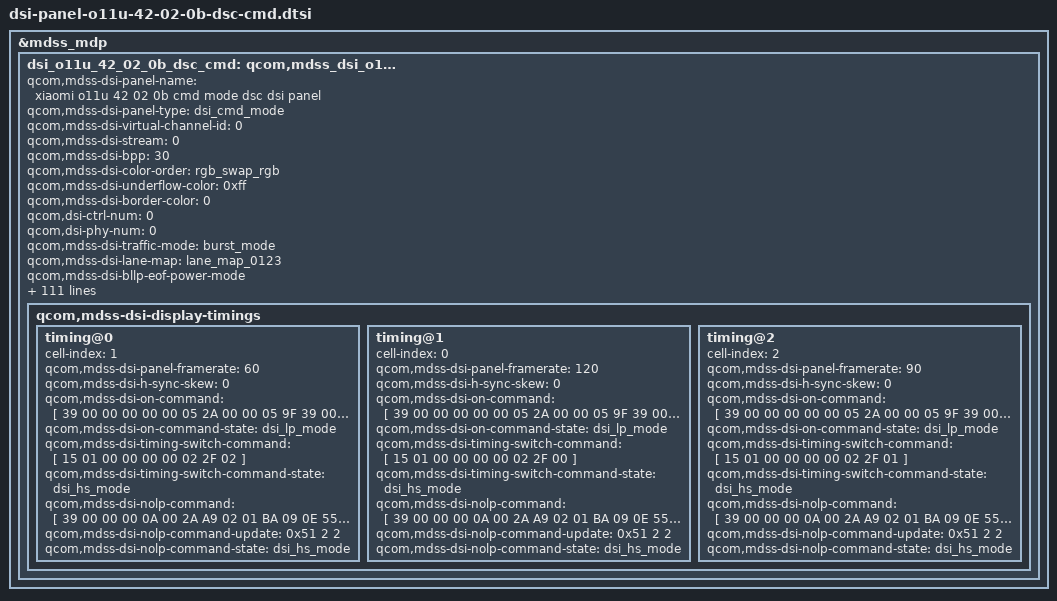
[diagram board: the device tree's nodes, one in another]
/* Panel Attention
 * 1.CCh must be 00 before 51h/26h/38h/39h/gamma change
 */

&mdss_mdp {
	dsi_o11u_42_02_0b_dsc_cmd: qcom,mdss_dsi_o11u_42_02_0b_dsc_cmd {
		qcom,mdss-dsi-panel-name = "xiaomi o11u 42 02 0b cmd mode dsc dsi panel";
		qcom,mdss-dsi-panel-type = "dsi_cmd_mode";
		qcom,mdss-dsi-virtual-channel-id = <0>;
		qcom,mdss-dsi-stream = <0>;
		qcom,mdss-dsi-bpp = <30>;
		qcom,mdss-dsi-color-order = "rgb_swap_rgb";
		qcom,mdss-dsi-underflow-color = <0xff>;
		qcom,mdss-dsi-border-color = <0>;
		qcom,dsi-ctrl-num = <0>;
		qcom,dsi-phy-num = <0>;

		qcom,mdss-dsi-traffic-mode = "burst_mode";
		qcom,mdss-dsi-lane-map = "lane_map_0123";
		qcom,mdss-dsi-bllp-eof-power-mode;
		qcom,mdss-dsi-bllp-power-mode;
		qcom,mdss-dsi-lane-0-state;
		qcom,mdss-dsi-lane-1-state;
		qcom,mdss-dsi-lane-2-state;
		qcom,mdss-dsi-lane-3-state;
		qcom,mdss-dsi-dma-trigger = "trigger_sw";
		qcom,mdss-dsi-mdp-trigger = "none";
		qcom,mdss-dsi-reset-sequence = <1 11>, <0 1>, <1 11>;
		qcom,mdss-pan-physical-width-dimension = <695>;
		qcom,mdss-pan-physical-height-dimension = <1545>;
		qcom,mdss-dsi-te-pin-select = <1>;
		qcom,mdss-dsi-wr-mem-start = <0x2c>;
		qcom,mdss-dsi-wr-mem-continue = <0x3c>;
		qcom,mdss-dsi-te-dcs-command = <1>;
		qcom,mdss-dsi-te-check-enable;
		qcom,mdss-dsi-te-using-te-pin;
		qcom,mdss-dsi-tx-eot-append;
		qcom,mdss-dsi-lp11-init;
		qcom,ulps-enabled;

		qcom,mdss-dsi-bl-inverted-dbv;
		qcom,bl-update-flag = "delay_until_first_frame";

		qcom,mdss-dsi-panel-hdr-enabled;
		qcom,mdss-dsi-panel-hdr-color-primaries = <14500 15500 32000
			17000 15500 30000 8000 3000>;
		qcom,mdss-dsi-panel-peak-brightness = <32000000>;
		qcom,mdss-dsi-panel-blackness-level = <3230>;

		qcom,mdss-dsi-dma-schedule-line = <1>;
		qcom,mdss-dsi-dma-schedule-window = <50>;
		qcom,panel-supply-entries = <&dsi_panel_pwr_supply_o11u>;
		qcom,panel-global-supply-entries = <&dsi_panel_pwr_supply_o11u>;
		qcom,mdss-dsi-bl-pmic-control-type = "bl_ctrl_dcs";
		qcom,mdss-dsi-bl-min-level = <15>;
		qcom,mdss-dsi-bl-max-level = <16383>;
		qcom,bl-dsc-cmd-state = "dsi_hs_mode";
		qcom,mdss-brightness-max-level = <16383>;
		qcom,mdss-brightness-init-level = <614>;
		qcom,platform-reset-gpio = <&tlmm 98 0>;
		qcom,mdss-dsi-panel-vsync-delay;
		qcom,dsi-select-clocks = "pll_byte_clk0", "pll_dsi_clk0";
		qcom,mdss-dsi-clk-strength = <0xFF>;

		qcom,mdss-dsi-display-timings {
			/* 60 Hz */
			timing@0 {
				#include "dsi-panel-o11u-42-02-0a-dsc-cmd-common.dtsi"
				cell-index = <1>;
				qcom,mdss-dsi-panel-framerate = <60>;
				qcom,mdss-dsi-h-sync-skew = <0>;
				qcom,mdss-dsi-on-command = [
					/* 1440 */
					39 00 00 00 00 00 05 2A 00 00 05 9F
					/* 3200 */
					39 00 00 00 00 00 05 2B 00 00 0C 7F
					/* IC SPR */
					39 00 00 40 00 00 03 90 03 43
					39 00 00 40 00 00 13 91 AB A8 00 14 C2 00 02 68 02 2E 00 0A 05 0E 03 D1 10 F0
					39 00 00 40 00 00 06 F0 55 AA 52 08 07
					39 00 00 00 00 00 06 B0 84 40 01 00 00
					/* 60 Hz cmd_1 */
					15 00 00 00 00 00 02 2F 02
					39 00 00 40 00 00 03 51 00 00
					/* idle_dbv */
					15 00 00 40 00 00 02 6F 04
					39 00 00 00 00 00 03 51 0F FF
					/* BCTRL=1 */
					15 00 00 00 00 00 02 53 20
					15 00 00 00 00 00 02 35 00
					15 00 00 40 00 00 02 6F 01
					/* DC_MODE=0 */
					15 00 00 00 00 00 02 8B 00
					/* AOD pulse */
					39 00 00 40 00 00 06 F0 55 AA 52 08 01
					15 00 00 40 00 00 02 6F A2
					39 00 00 40 00 00 06 E7 FF FF FF FF FF
					15 00 00 40 00 00 02 6F 11
					15 00 00 00 00 00 02 E7 08
					/* Show Demura */
					39 00 00 40 00 00 06 F0 55 AA 52 08 00
					15 00 00 40 00 00 02 C7 33
					15 00 00 40 00 00 02 6F 31
					39 00 00 40 00 00 03 C0 00 10
					15 00 00 40 00 00 02 6F 35
					39 00 00 40 00 00 03 C0 22 40
					39 00 00 40 00 00 06 F0 55 AA 52 08 04
					15 00 00 00 00 00 02 C0 20
					/* Demura ON */
					39 00 00 40 00 00 06 F0 55 AA 52 08 04
					15 00 00 00 00 00 02 CA 01
					/* VP_HSSI=1.1 */
					39 00 00 40 00 00 06 F0 55 AA 52 08 01
					15 00 00 40 00 00 02 6F 05
					39 00 00 00 00 00 04 E7 C5 0A 0A
					/* OD ON*/
					39 00 00 40 00 00 06 F0 55 AA 52 08 08
					39 00 00 40 00 00 07 E8 11 90 00 00 00 20
					15 00 00 40 00 00 02 6F 06
					39 00 00 40 00 00 18 E8 00 70 74 74 78 78 7C 7C 7C 7C 7C 7C 7C 7C 78 78 74 74 70 70 64 64 64
					15 00 00 40 00 00 02 6F 1D
					39 00 00 40 00 00 18 E8 00 64 6C 6C 80 80 88 88 88 88 8C 8C 8C 8C 88 88 84 84 84 84 70 70 70
					15 00 00 40 00 00 02 6F 34
					39 00 00 40 00 00 18 E8 00 A4 A8 A8 A8 A8 A8 A8 AC AC AC AC AC AC A8 A8 A4 A4 A4 A4 8C 8C 8C
					39 00 00 40 00 00 06 F0 55 AA 52 08 08
					39 00 00 40 00 00 05 E0 01 01 01 01
					15 00 00 40 00 00 02 6F 06
					39 00 00 40 00 00 0E E0 80 00 21 32 43 54 65 76 87 98 99 99 99
					39 00 00 40 00 00 0F E1 00 00 00 00 00 00 00 00 00 00 01 01 03 03
					15 00 00 40 00 00 02 6F 0E
					39 00 00 40 00 00 0F E1 00 00 00 00 00 00 00 00 00 03 03 03 06 07
					15 00 00 40 00 00 02 6F 1C
					39 00 00 40 00 00 0F E1 00 00 00 00 00 00 00 00 01 02 04 05 0A 0B
					15 00 00 40 00 00 02 6F 2A
					39 00 00 40 00 00 0F E1 00 00 00 00 00 00 00 00 03 04 06 07 0B 0C
					15 00 00 40 00 00 02 6F 38
					39 00 00 40 00 00 0F E1 00 00 00 00 00 00 01 01 04 07 09 0A 0C 0E
					15 00 00 40 00 00 02 6F 46
					39 00 00 40 00 00 0F E1 00 00 00 00 01 01 01 03 04 06 07 09 0A 0B
					15 00 00 40 00 00 02 6F 54
					39 00 00 40 00 00 0F E1 00 00 00 00 01 01 01 03 04 06 07 09 0A 0B
					15 00 00 40 00 00 02 6F 62
					39 00 00 40 00 00 0F E1 00 00 00 00 00 01 01 01 03 05 08 0C 0D 0E
					15 00 00 40 00 00 02 6F 70
					39 00 00 40 00 00 0F E1 00 00 00 00 01 02 02 03 05 06 09 0B 0E 10
					39 00 00 40 00 00 0F E2 01 01 01 02 19 1A 10 0F 0F 17 08 12 15 1E
					15 00 00 40 00 00 02 6F 0E
					39 00 00 40 00 00 0F E2 04 08 0B 0F 11 11 13 13 0C 0C 0A 0B 12 13
					15 00 00 40 00 00 02 6F 1C
					39 00 00 40 00 00 0F E2 02 04 05 07 0A 0D 0F 0D 06 09 0A 0E 0F 10
					15 00 00 40 00 00 02 6F 2A
					39 00 00 40 00 00 0F E2 02 04 0A 0B 02 03 06 07 07 09 0B 0C 0F 12
					15 00 00 40 00 00 02 6F 38
					39 00 00 40 00 00 0F E2 03 05 05 08 02 02 04 05 05 08 0B 0D 10 11
					15 00 00 40 00 00 02 6F 46
					39 00 00 40 00 00 0F E2 02 02 03 05 02 01 04 05 07 09 0A 0C 0F 11
					15 00 00 40 00 00 02 6F 54
					39 00 00 40 00 00 0F E2 02 02 03 05 02 01 04 05 07 09 0A 0C 0F 11
					15 00 00 40 00 00 02 6F 62
					39 00 00 40 00 00 0F E2 01 01 02 02 01 01 03 03 07 08 09 0D 0D 11
					15 00 00 40 00 00 02 6F 70
					39 00 00 40 00 00 0F E2 00 00 01 01 01 01 03 04 06 08 09 0B 0F 11
					39 00 00 40 00 00 0F E3 00 00 00 00 00 00 00 00 00 00 02 02 07 07
					15 00 00 40 00 00 02 6F 0E
					39 00 00 40 00 00 0F E3 00 00 00 00 00 00 01 01 01 02 04 04 0E 0E
					15 00 00 40 00 00 02 6F 1C
					39 00 00 40 00 00 0F E3 00 00 00 00 00 01 01 01 01 04 03 05 08 0E
					15 00 00 40 00 00 02 6F 2A
					39 00 00 40 00 00 0F E3 00 00 00 00 00 01 02 02 02 06 08 0C 0D 0F
					15 00 00 40 00 00 02 6F 38
					39 00 00 40 00 00 0F E3 00 00 00 00 00 01 02 02 05 06 0A 0A 0C 0F
					15 00 00 40 00 00 02 6F 46
					39 00 00 40 00 00 0F E3 00 00 00 00 00 01 02 02 04 07 06 0A 0B 0D
					15 00 00 40 00 00 02 6F 54
					39 00 00 40 00 00 0F E3 00 00 00 00 00 01 02 02 04 07 06 0A 0B 0D
					15 00 00 40 00 00 02 6F 62
					39 00 00 40 00 00 0F E3 00 00 01 01 01 02 03 04 05 07 0A 0C 0F 11
					15 00 00 40 00 00 02 6F 70
					39 00 00 40 00 00 0F E3 00 01 01 01 01 01 02 03 06 07 0A 0D 0F 12
					39 00 00 40 00 00 1C EA 00 00 00 00 00 00 00 00 00 00 00 00 00 00 00 00 00 00 00 00 00 00 00 00 00 00 00
					39 00 00 40 00 00 0A E4 00 00 00 00 00 00 00 00 00
					39 00 00 40 00 00 0A E5 00 00 00 00 00 00 00 00 00
					39 00 00 40 00 00 0A E6 00 00 00 00 00 00 00 00 00
					39 00 00 40 00 00 06 F0 55 AA 52 08 08
					15 00 00 40 00 00 02 E8 11
					15 00 00 00 00 00 02 E0 01
					/* ESD ERR Flag */
					39 00 00 40 00 00 06 F0 55 AA 52 08 00
					39 00 00 40 00 00 03 BE 47 45
					15 00 00 40 00 00 02 6F 05
					15 00 00 00 00 00 02 BE 08
					/*  ESD MIPI error */
					39 00 00 40 00 00 06 F0 55 AA 52 08 03
					39 00 00 00 00 00 04 C8 01 02 03
					/* MIPI error */
					39 00 00 40 00 00 05 FF AA 55 A5 80
					15 00 00 40 00 00 02 6F 22
					15 00 00 00 00 00 02 FE 06
					/*MIPI optimize code1 */
					39 00 00 40 00 00 05 FF AA 55 A5 82
					15 00 00 40 00 00 02 6F 05
					15 00 00 00 00 00 02 F3 11
					/*MIPI optimize code2 */
					39 00 00 40 00 00 06 F0 55 AA 52 08 01
					15 00 00 40 00 00 02 6F 05
					39 00 00 00 00 00 03 C5 0A 0A
					/* APL Data scaling */
					39 00 00 40 00 00 06 F0 55 AA 52 08 00
					15 00 00 40 00 00 02 6F 78
					39 00 00 40 00 00 18 B0 11 00 2A 00 C2 01 DA 03 7C 05 B1 08 80 0B EE 0F FF 05 55 05 56 05 55
					15 00 00 40 00 00 02 6F 6F
					39 00 00 40 00 00 07 B0 02 D0 05 A0 02 D0
					39 00 00 40 00 00 06 F0 55 AA 52 08 08
					39 00 00 40 00 00 17 C1 8C FF CC FF FF CC FF FF CC FF FF EC FF 7F EE 7F 7F FF 7F FF 0E 7F
					15 00 00 40 00 00 02 6F 20
					39 00 00 40 00 00 04 C1 4F 00 FF
					15 00 00 40 00 00 02 6F 23
					39 00 00 00 00 00 15 C1 0C FF CC FF FF CC FF FF CC FF FF EC FF 7F EE 7F 7F CF 7F 0A
					/* Round ON */
					39 00 00 40 00 00 06 F0 55 AA 52 08 07
					15 00 00 00 00 00 02 C0 87
					/* OSC=125.2MHz, 1200Mbps */
					39 00 00 00 00 00 EE A9 02 01 C3 00 00 99 02 01 C3 30 30 00 02 01 C3 0B 0D 3F 20 2F 02 01 C3 11 13 3F 70 2F 02 01 C3 17 17 3F 02 01 C3 18 19 26 2F 02 01 C3 1D 1F 3F 20 2F 02 01 C3 23 25 3F 3A 2F 02 01 C3 0E 0F 3F 62 02 01 C3 10 10 DE 02 01 C3 14 16 3F 62 DE 02 01 C3 1A 1C 3F 62 DE 02 01 C3 20 22 3F 62 DE 02 01 C3 26 27 3F 62 02 01 C3 28 28 DE 02 01 C3 29 2B 11 11 01 02 01 C3 2C 2E 00 00 00 02 01 C3 31 32 AA 02 02 01 C3 33 34 AA 02 02 01 C3 04 04 E3 02 01 C3 09 09 E4 02 01 C3 01 01 29 02 01 C3 06 06 29 02 01 C3 02 03 02 70 02 01 C3 08 08 70 02 01 EA 00 00 11 02 01 EA 07 07 01 02 01 EA 08 08 39 02 01 EA 0B 0B 11 02 01 EA 12 13 01 AC 02 01 EA 1A 1B 01 39 02 01 EA 1C 1D 01 AC 02 01 C3 04 04 EA 02 01 C3 09 09 EA 02 01 C3 2F 2F 77
					/*DDIC Fast Discharge On*/
					39 00 00 40 00 00 06 F0 55 AA 52 08 01
					15 00 00 40 00 00 02 E4 90
					15 00 00 40 00 00 02 6F 0A
					15 00 00 00 00 00 02 E4 90
					/* Fix TE Width */
					39 00 00 00 00 00 03 35 20 2E
					/* Abnormal power failure */
					39 00 00 00 00 00 06 F0 55 AA 52 08 05
					39 00 00 00 00 00 08 CB 13 13 13 13 13 13 13
					/* Sleep Out */
					05 00 00 00 78 00 02 11 00
					/* Demura offset remapping open */
					39 00 00 40 00 00 06 F0 55 AA 52 08 04
					15 00 00 00 00 00 02 EB 00
					/* Display On */
					05 00 00 00 00 00 02 29 00
				];
				qcom,mdss-dsi-on-command-state = "dsi_lp_mode";
				qcom,mdss-dsi-timing-switch-command = [
					/* 60 Hz cmd_1 */
					15 01 00 00 00 00 02 2F 02
				];
				qcom,mdss-dsi-timing-switch-command-state = "dsi_hs_mode";

				qcom,mdss-dsi-nolp-command = [
					39 00 00 00 0A 00 2A A9 02 01 BA 09 0E 55 55 55 55 AA 3F 02 01 BA 1B 1C 92 92 02 01 BA 27 27 55 02 01 BA 28 2C 55 55 55 AA 3F 02 01 BA 39 3A 92 92
					05 00 00 40 00 00 01 38
					39 00 00 40 00 00 03 51 00 23
					15 00 00 00 00 00 02 2F 02
				];
				qcom,mdss-dsi-nolp-command-update = <0x51 2 2>;
				qcom,mdss-dsi-nolp-command-state = "dsi_hs_mode";

			};

			/* 120 Hz */
			timing@1 {
				#include "dsi-panel-o11u-42-02-0a-dsc-cmd-common.dtsi"
				cell-index = <0>;
				qcom,mdss-dsi-panel-framerate = <120>;
				qcom,mdss-dsi-h-sync-skew = <0>;
				qcom,mdss-dsi-on-command = [
					/* 1440 */
					39 00 00 00 00 00 05 2A 00 00 05 9F
					/* 3200 */
					39 00 00 00 00 00 05 2B 00 00 0C 7F
					/* IC SPR */
					39 00 00 40 00 00 03 90 03 43
					39 00 00 40 00 00 13 91 AB A8 00 14 C2 00 02 68 02 2E 00 0A 05 0E 03 D1 10 F0
					39 00 00 40 00 00 06 F0 55 AA 52 08 07
					39 00 00 00 00 00 06 B0 84 40 01 00 00
					/* 120 Hz cmd_1 */
					15 00 00 00 00 00 02 2F 00
					39 00 00 40 00 00 03 51 00 00
					/* idle_dbv */
					15 00 00 40 00 00 02 6F 04
					39 00 00 00 00 00 03 51 0F FF
					/* BCTRL=1 */
					15 00 00 00 00 00 02 53 20
					15 00 00 00 00 00 02 35 00
					15 00 00 40 00 00 02 6F 01
					/* DC_MODE=0 */
					15 00 00 00 00 00 02 8B 00
					/* AOD pulse */
					39 00 00 40 00 00 06 F0 55 AA 52 08 01
					15 00 00 40 00 00 02 6F A2
					39 00 00 40 00 00 06 E7 FF FF FF FF FF
					15 00 00 40 00 00 02 6F 11
					15 00 00 00 00 00 02 E7 08
					/* Show Demura */
					39 00 00 40 00 00 06 F0 55 AA 52 08 00
					15 00 00 40 00 00 02 C7 33
					15 00 00 40 00 00 02 6F 31
					39 00 00 40 00 00 03 C0 00 10
					15 00 00 40 00 00 02 6F 35
					39 00 00 40 00 00 03 C0 22 40
					39 00 00 40 00 00 06 F0 55 AA 52 08 04
					15 00 00 00 00 00 02 C0 20
					/* Demura ON */
					39 00 00 40 00 00 06 F0 55 AA 52 08 04
					15 00 00 00 00 00 02 CA 01
					/* VP_HSSI=1.1 */
					39 00 00 40 00 00 06 F0 55 AA 52 08 01
					15 00 00 40 00 00 02 6F 05
					39 00 00 00 00 00 04 E7 C5 0A 0A
					/* OD ON*/
					39 00 00 40 00 00 06 F0 55 AA 52 08 08
					39 00 00 40 00 00 07 E8 11 90 00 00 00 20
					15 00 00 40 00 00 02 6F 06
					39 00 00 40 00 00 18 E8 00 70 74 74 78 78 7C 7C 7C 7C 7C 7C 7C 7C 78 78 74 74 70 70 64 64 64
					15 00 00 40 00 00 02 6F 1D
					39 00 00 40 00 00 18 E8 00 64 6C 6C 80 80 88 88 88 88 8C 8C 8C 8C 88 88 84 84 84 84 70 70 70
					15 00 00 40 00 00 02 6F 34
					39 00 00 40 00 00 18 E8 00 A4 A8 A8 A8 A8 A8 A8 AC AC AC AC AC AC A8 A8 A4 A4 A4 A4 8C 8C 8C
					39 00 00 40 00 00 06 F0 55 AA 52 08 08
					39 00 00 40 00 00 05 E0 01 01 01 01
					15 00 00 40 00 00 02 6F 06
					39 00 00 40 00 00 0E E0 80 00 21 32 43 54 65 76 87 98 99 99 99
					39 00 00 40 00 00 0F E1 00 00 00 00 00 00 00 00 00 00 01 01 03 03
					15 00 00 40 00 00 02 6F 0E
					39 00 00 40 00 00 0F E1 00 00 00 00 00 00 00 00 00 03 03 03 06 07
					15 00 00 40 00 00 02 6F 1C
					39 00 00 40 00 00 0F E1 00 00 00 00 00 00 00 00 01 02 04 05 0A 0B
					15 00 00 40 00 00 02 6F 2A
					39 00 00 40 00 00 0F E1 00 00 00 00 00 00 00 00 03 04 06 07 0B 0C
					15 00 00 40 00 00 02 6F 38
					39 00 00 40 00 00 0F E1 00 00 00 00 00 00 01 01 04 07 09 0A 0C 0E
					15 00 00 40 00 00 02 6F 46
					39 00 00 40 00 00 0F E1 00 00 00 00 01 01 01 03 04 06 07 09 0A 0B
					15 00 00 40 00 00 02 6F 54
					39 00 00 40 00 00 0F E1 00 00 00 00 01 01 01 03 04 06 07 09 0A 0B
					15 00 00 40 00 00 02 6F 62
					39 00 00 40 00 00 0F E1 00 00 00 00 00 01 01 01 03 05 08 0C 0D 0E
					15 00 00 40 00 00 02 6F 70
					39 00 00 40 00 00 0F E1 00 00 00 00 01 02 02 03 05 06 09 0B 0E 10
					39 00 00 40 00 00 0F E2 01 01 01 02 19 1A 10 0F 0F 17 08 12 15 1E
					15 00 00 40 00 00 02 6F 0E
					39 00 00 40 00 00 0F E2 04 08 0B 0F 11 11 13 13 0C 0C 0A 0B 12 13
					15 00 00 40 00 00 02 6F 1C
					39 00 00 40 00 00 0F E2 02 04 05 07 0A 0D 0F 0D 06 09 0A 0E 0F 10
					15 00 00 40 00 00 02 6F 2A
					39 00 00 40 00 00 0F E2 02 04 0A 0B 02 03 06 07 07 09 0B 0C 0F 12
					15 00 00 40 00 00 02 6F 38
					39 00 00 40 00 00 0F E2 03 05 05 08 02 02 04 05 05 08 0B 0D 10 11
					15 00 00 40 00 00 02 6F 46
					39 00 00 40 00 00 0F E2 02 02 03 05 02 01 04 05 07 09 0A 0C 0F 11
					15 00 00 40 00 00 02 6F 54
					39 00 00 40 00 00 0F E2 02 02 03 05 02 01 04 05 07 09 0A 0C 0F 11
					15 00 00 40 00 00 02 6F 62
					39 00 00 40 00 00 0F E2 01 01 02 02 01 01 03 03 07 08 09 0D 0D 11
					15 00 00 40 00 00 02 6F 70
					39 00 00 40 00 00 0F E2 00 00 01 01 01 01 03 04 06 08 09 0B 0F 11
					39 00 00 40 00 00 0F E3 00 00 00 00 00 00 00 00 00 00 02 02 07 07
					15 00 00 40 00 00 02 6F 0E
					39 00 00 40 00 00 0F E3 00 00 00 00 00 00 01 01 01 02 04 04 0E 0E
					15 00 00 40 00 00 02 6F 1C
					39 00 00 40 00 00 0F E3 00 00 00 00 00 01 01 01 01 04 03 05 08 0E
					15 00 00 40 00 00 02 6F 2A
					39 00 00 40 00 00 0F E3 00 00 00 00 00 01 02 02 02 06 08 0C 0D 0F
					15 00 00 40 00 00 02 6F 38
					39 00 00 40 00 00 0F E3 00 00 00 00 00 01 02 02 05 06 0A 0A 0C 0F
					15 00 00 40 00 00 02 6F 46
					39 00 00 40 00 00 0F E3 00 00 00 00 00 01 02 02 04 07 06 0A 0B 0D
					15 00 00 40 00 00 02 6F 54
					39 00 00 40 00 00 0F E3 00 00 00 00 00 01 02 02 04 07 06 0A 0B 0D
					15 00 00 40 00 00 02 6F 62
					39 00 00 40 00 00 0F E3 00 00 01 01 01 02 03 04 05 07 0A 0C 0F 11
					15 00 00 40 00 00 02 6F 70
					39 00 00 40 00 00 0F E3 00 01 01 01 01 01 02 03 06 07 0A 0D 0F 12
					39 00 00 40 00 00 1C EA 00 00 00 00 00 00 00 00 00 00 00 00 00 00 00 00 00 00 00 00 00 00 00 00 00 00 00
					39 00 00 40 00 00 0A E4 00 00 00 00 00 00 00 00 00
					39 00 00 40 00 00 0A E5 00 00 00 00 00 00 00 00 00
					39 00 00 40 00 00 0A E6 00 00 00 00 00 00 00 00 00
					39 00 00 40 00 00 06 F0 55 AA 52 08 08
					15 00 00 40 00 00 02 E8 11
					15 00 00 00 00 00 02 E0 01
					/* ESD ERR Flag */
					39 00 00 40 00 00 06 F0 55 AA 52 08 00
					39 00 00 40 00 00 03 BE 47 45
					15 00 00 40 00 00 02 6F 05
					15 00 00 00 00 00 02 BE 08
					/*  ESD MIPI error */
					39 00 00 40 00 00 06 F0 55 AA 52 08 03
					39 00 00 00 00 00 04 C8 01 02 03
					/* MIPI error */
					39 00 00 40 00 00 05 FF AA 55 A5 80
					15 00 00 40 00 00 02 6F 22
					15 00 00 00 00 00 02 FE 06
					/*MIPI optimize code1 */
					39 00 00 40 00 00 05 FF AA 55 A5 82
					15 00 00 40 00 00 02 6F 05
					15 00 00 00 00 00 02 F3 11
					/*MIPI optimize code2 */
					39 00 00 40 00 00 06 F0 55 AA 52 08 01
					15 00 00 40 00 00 02 6F 05
					39 00 00 00 00 00 03 C5 0A 0A
					/* APL Data scaling */
					39 00 00 40 00 00 06 F0 55 AA 52 08 00
					15 00 00 40 00 00 02 6F 78
					39 00 00 40 00 00 18 B0 11 00 2A 00 C2 01 DA 03 7C 05 B1 08 80 0B EE 0F FF 05 55 05 56 05 55
					15 00 00 40 00 00 02 6F 6F
					39 00 00 40 00 00 07 B0 02 D0 05 A0 02 D0
					39 00 00 40 00 00 06 F0 55 AA 52 08 08
					39 00 00 40 00 00 17 C1 8C FF CC FF FF CC FF FF CC FF FF EC FF 7F EE 7F 7F FF 7F FF 0E 7F
					15 00 00 40 00 00 02 6F 20
					39 00 00 40 00 00 04 C1 4F 00 FF
					15 00 00 40 00 00 02 6F 23
					39 00 00 00 00 00 15 C1 0C FF CC FF FF CC FF FF CC FF FF EC FF 7F EE 7F 7F CF 7F 0A
					/* Round ON */
					39 00 00 40 00 00 06 F0 55 AA 52 08 07
					15 00 00 00 00 00 02 C0 87
					/* OSC=125.2MHz, 1200Mbps */
					39 00 00 00 00 00 EE A9 02 01 C3 00 00 99 02 01 C3 30 30 00 02 01 C3 0B 0D 3F 20 2F 02 01 C3 11 13 3F 70 2F 02 01 C3 17 17 3F 02 01 C3 18 19 26 2F 02 01 C3 1D 1F 3F 20 2F 02 01 C3 23 25 3F 3A 2F 02 01 C3 0E 0F 3F 62 02 01 C3 10 10 DE 02 01 C3 14 16 3F 62 DE 02 01 C3 1A 1C 3F 62 DE 02 01 C3 20 22 3F 62 DE 02 01 C3 26 27 3F 62 02 01 C3 28 28 DE 02 01 C3 29 2B 11 11 01 02 01 C3 2C 2E 00 00 00 02 01 C3 31 32 AA 02 02 01 C3 33 34 AA 02 02 01 C3 04 04 E3 02 01 C3 09 09 E4 02 01 C3 01 01 29 02 01 C3 06 06 29 02 01 C3 02 03 02 70 02 01 C3 08 08 70 02 01 EA 00 00 11 02 01 EA 07 07 01 02 01 EA 08 08 39 02 01 EA 0B 0B 11 02 01 EA 12 13 01 AC 02 01 EA 1A 1B 01 39 02 01 EA 1C 1D 01 AC 02 01 C3 04 04 EA 02 01 C3 09 09 EA 02 01 C3 2F 2F 77
					/*DDIC Fast Discharge On*/
					39 00 00 40 00 00 06 F0 55 AA 52 08 01
					15 00 00 40 00 00 02 E4 90
					15 00 00 40 00 00 02 6F 0A
					15 00 00 00 00 00 02 E4 90
					/* Fix TE Width */
					39 00 00 00 00 00 03 35 20 2E
					/* Abnormal power failure */
					39 00 00 00 00 00 06 F0 55 AA 52 08 05
					39 00 00 00 00 00 08 CB 13 13 13 13 13 13 13
					/* Sleep Out */
					05 00 00 00 78 00 02 11 00
					/* Demura offset remapping open */
					39 00 00 40 00 00 06 F0 55 AA 52 08 04
					15 00 00 00 00 00 02 EB 00
					/* Display On */
					05 00 00 00 00 00 02 29 00
				];
				qcom,mdss-dsi-on-command-state = "dsi_lp_mode";

				qcom,mdss-dsi-timing-switch-command = [
					/* 120 Hz cmd_1 */
					15 01 00 00 00 00 02 2F 00
				];
				qcom,mdss-dsi-timing-switch-command-state = "dsi_hs_mode";

				qcom,mdss-dsi-nolp-command = [
					39 00 00 00 0A 00 2A A9 02 01 BA 09 0E 55 55 55 55 AA 3F 02 01 BA 1B 1C 92 92 02 01 BA 27 27 55 02 01 BA 28 2C 55 55 55 AA 3F 02 01 BA 39 3A 92 92
					05 00 00 40 00 00 01 38
					39 00 00 40 00 00 03 51 00 23
					15 00 00 00 00 00 02 2F 00
				];
				qcom,mdss-dsi-nolp-command-update = <0x51 2 2>;
				qcom,mdss-dsi-nolp-command-state = "dsi_hs_mode";
			};

			/* 90 Hz */
			timing@2 {
				#include "dsi-panel-o11u-42-02-0a-dsc-cmd-common.dtsi"
				cell-index = <2>;
				qcom,mdss-dsi-panel-framerate = <90>;
				qcom,mdss-dsi-h-sync-skew = <0>;
				qcom,mdss-dsi-on-command = [
					/* 1440 */
					39 00 00 00 00 00 05 2A 00 00 05 9F
					/* 3200 */
					39 00 00 00 00 00 05 2B 00 00 0C 7F
					/* IC SPR */
					39 00 00 40 00 00 03 90 03 43
					39 00 00 40 00 00 13 91 AB A8 00 14 C2 00 02 68 02 2E 00 0A 05 0E 03 D1 10 F0
					39 00 00 40 00 00 06 F0 55 AA 52 08 07
					39 00 00 00 00 00 06 B0 84 40 01 00 00
					/* 90 Hz cmd_1 */
					15 00 00 00 00 00 02 2F 01
					39 00 00 40 00 00 03 51 00 00
					/* idle_dbv */
					15 00 00 40 00 00 02 6F 04
					39 00 00 00 00 00 03 51 0F FF
					/* BCTRL=1 */
					15 00 00 00 00 00 02 53 20
					15 00 00 00 00 00 02 35 00
					15 00 00 40 00 00 02 6F 01
					/* DC_MODE=0 */
					15 00 00 00 00 00 02 8B 00
					/* AOD pulse */
					39 00 00 40 00 00 06 F0 55 AA 52 08 01
					15 00 00 40 00 00 02 6F A2
					39 00 00 40 00 00 06 E7 FF FF FF FF FF
					15 00 00 40 00 00 02 6F 11
					15 00 00 00 00 00 02 E7 08
					/* Show Demura */
					39 00 00 40 00 00 06 F0 55 AA 52 08 00
					15 00 00 40 00 00 02 C7 33
					15 00 00 40 00 00 02 6F 31
					39 00 00 40 00 00 03 C0 00 10
					15 00 00 40 00 00 02 6F 35
					39 00 00 40 00 00 03 C0 22 40
					39 00 00 40 00 00 06 F0 55 AA 52 08 04
					15 00 00 00 00 00 02 C0 20
					/* Demura ON */
					39 00 00 40 00 00 06 F0 55 AA 52 08 04
					15 00 00 00 00 00 02 CA 01
					/* VP_HSSI=1.1 */
					39 00 00 40 00 00 06 F0 55 AA 52 08 01
					15 00 00 40 00 00 02 6F 05
					39 00 00 00 00 00 04 E7 C5 0A 0A
					/* OD ON*/
					39 00 00 40 00 00 06 F0 55 AA 52 08 08
					39 00 00 40 00 00 07 E8 11 90 00 00 00 20
					15 00 00 40 00 00 02 6F 06
					39 00 00 40 00 00 18 E8 00 70 74 74 78 78 7C 7C 7C 7C 7C 7C 7C 7C 78 78 74 74 70 70 64 64 64
					15 00 00 40 00 00 02 6F 1D
					39 00 00 40 00 00 18 E8 00 64 6C 6C 80 80 88 88 88 88 8C 8C 8C 8C 88 88 84 84 84 84 70 70 70
					15 00 00 40 00 00 02 6F 34
					39 00 00 40 00 00 18 E8 00 A4 A8 A8 A8 A8 A8 A8 AC AC AC AC AC AC A8 A8 A4 A4 A4 A4 8C 8C 8C
					39 00 00 40 00 00 06 F0 55 AA 52 08 08
					39 00 00 40 00 00 05 E0 01 01 01 01
					15 00 00 40 00 00 02 6F 06
					39 00 00 40 00 00 0E E0 80 00 21 32 43 54 65 76 87 98 99 99 99
					39 00 00 40 00 00 0F E1 00 00 00 00 00 00 00 00 00 00 01 01 03 03
					15 00 00 40 00 00 02 6F 0E
					39 00 00 40 00 00 0F E1 00 00 00 00 00 00 00 00 00 03 03 03 06 07
					15 00 00 40 00 00 02 6F 1C
					39 00 00 40 00 00 0F E1 00 00 00 00 00 00 00 00 01 02 04 05 0A 0B
					15 00 00 40 00 00 02 6F 2A
					39 00 00 40 00 00 0F E1 00 00 00 00 00 00 00 00 03 04 06 07 0B 0C
					15 00 00 40 00 00 02 6F 38
					39 00 00 40 00 00 0F E1 00 00 00 00 00 00 01 01 04 07 09 0A 0C 0E
					15 00 00 40 00 00 02 6F 46
					39 00 00 40 00 00 0F E1 00 00 00 00 01 01 01 03 04 06 07 09 0A 0B
					15 00 00 40 00 00 02 6F 54
					39 00 00 40 00 00 0F E1 00 00 00 00 01 01 01 03 04 06 07 09 0A 0B
					15 00 00 40 00 00 02 6F 62
					39 00 00 40 00 00 0F E1 00 00 00 00 00 01 01 01 03 05 08 0C 0D 0E
					15 00 00 40 00 00 02 6F 70
					39 00 00 40 00 00 0F E1 00 00 00 00 01 02 02 03 05 06 09 0B 0E 10
					39 00 00 40 00 00 0F E2 01 01 01 02 19 1A 10 0F 0F 17 08 12 15 1E
					15 00 00 40 00 00 02 6F 0E
					39 00 00 40 00 00 0F E2 04 08 0B 0F 11 11 13 13 0C 0C 0A 0B 12 13
					15 00 00 40 00 00 02 6F 1C
					39 00 00 40 00 00 0F E2 02 04 05 07 0A 0D 0F 0D 06 09 0A 0E 0F 10
					15 00 00 40 00 00 02 6F 2A
					39 00 00 40 00 00 0F E2 02 04 0A 0B 02 03 06 07 07 09 0B 0C 0F 12
					15 00 00 40 00 00 02 6F 38
					39 00 00 40 00 00 0F E2 03 05 05 08 02 02 04 05 05 08 0B 0D 10 11
					15 00 00 40 00 00 02 6F 46
					39 00 00 40 00 00 0F E2 02 02 03 05 02 01 04 05 07 09 0A 0C 0F 11
					15 00 00 40 00 00 02 6F 54
					39 00 00 40 00 00 0F E2 02 02 03 05 02 01 04 05 07 09 0A 0C 0F 11
					15 00 00 40 00 00 02 6F 62
					39 00 00 40 00 00 0F E2 01 01 02 02 01 01 03 03 07 08 09 0D 0D 11
					15 00 00 40 00 00 02 6F 70
					39 00 00 40 00 00 0F E2 00 00 01 01 01 01 03 04 06 08 09 0B 0F 11
					39 00 00 40 00 00 0F E3 00 00 00 00 00 00 00 00 00 00 02 02 07 07
					15 00 00 40 00 00 02 6F 0E
					39 00 00 40 00 00 0F E3 00 00 00 00 00 00 01 01 01 02 04 04 0E 0E
					15 00 00 40 00 00 02 6F 1C
					39 00 00 40 00 00 0F E3 00 00 00 00 00 01 01 01 01 04 03 05 08 0E
					15 00 00 40 00 00 02 6F 2A
					39 00 00 40 00 00 0F E3 00 00 00 00 00 01 02 02 02 06 08 0C 0D 0F
					15 00 00 40 00 00 02 6F 38
					39 00 00 40 00 00 0F E3 00 00 00 00 00 01 02 02 05 06 0A 0A 0C 0F
					15 00 00 40 00 00 02 6F 46
					39 00 00 40 00 00 0F E3 00 00 00 00 00 01 02 02 04 07 06 0A 0B 0D
					15 00 00 40 00 00 02 6F 54
					39 00 00 40 00 00 0F E3 00 00 00 00 00 01 02 02 04 07 06 0A 0B 0D
					15 00 00 40 00 00 02 6F 62
					39 00 00 40 00 00 0F E3 00 00 01 01 01 02 03 04 05 07 0A 0C 0F 11
					15 00 00 40 00 00 02 6F 70
					39 00 00 40 00 00 0F E3 00 01 01 01 01 01 02 03 06 07 0A 0D 0F 12
					39 00 00 40 00 00 1C EA 00 00 00 00 00 00 00 00 00 00 00 00 00 00 00 00 00 00 00 00 00 00 00 00 00 00 00
					39 00 00 40 00 00 0A E4 00 00 00 00 00 00 00 00 00
					39 00 00 40 00 00 0A E5 00 00 00 00 00 00 00 00 00
					39 00 00 40 00 00 0A E6 00 00 00 00 00 00 00 00 00
					39 00 00 40 00 00 06 F0 55 AA 52 08 08
					15 00 00 40 00 00 02 E8 11
					15 00 00 00 00 00 02 E0 01
					/* ESD ERR Flag */
					39 00 00 40 00 00 06 F0 55 AA 52 08 00
					39 00 00 40 00 00 03 BE 47 45
					15 00 00 40 00 00 02 6F 05
					15 00 00 00 00 00 02 BE 08
					/*  ESD MIPI error */
					39 00 00 40 00 00 06 F0 55 AA 52 08 03
					39 00 00 00 00 00 04 C8 01 02 03
					/* MIPI error */
					39 00 00 40 00 00 05 FF AA 55 A5 80
					15 00 00 40 00 00 02 6F 22
					15 00 00 00 00 00 02 FE 06
					/*MIPI optimize code1 */
					39 00 00 40 00 00 05 FF AA 55 A5 82
					15 00 00 40 00 00 02 6F 05
					15 00 00 00 00 00 02 F3 11
					/*MIPI optimize code2 */
					39 00 00 40 00 00 06 F0 55 AA 52 08 01
					15 00 00 40 00 00 02 6F 05
					39 00 00 00 00 00 03 C5 0A 0A
					/* APL Data scaling */
					39 00 00 40 00 00 06 F0 55 AA 52 08 00
					15 00 00 40 00 00 02 6F 78
					39 00 00 40 00 00 18 B0 11 00 2A 00 C2 01 DA 03 7C 05 B1 08 80 0B EE 0F FF 05 55 05 56 05 55
					15 00 00 40 00 00 02 6F 6F
					39 00 00 40 00 00 07 B0 02 D0 05 A0 02 D0
					39 00 00 40 00 00 06 F0 55 AA 52 08 08
					39 00 00 40 00 00 17 C1 8C FF CC FF FF CC FF FF CC FF FF EC FF 7F EE 7F 7F FF 7F FF 0E 7F
					15 00 00 40 00 00 02 6F 20
					39 00 00 40 00 00 04 C1 4F 00 FF
					15 00 00 40 00 00 02 6F 23
					39 00 00 00 00 00 15 C1 0C FF CC FF FF CC FF FF CC FF FF EC FF 7F EE 7F 7F CF 7F 0A
					/* Round ON */
					39 00 00 40 00 00 06 F0 55 AA 52 08 07
					15 00 00 00 00 00 02 C0 87
					/* OSC=125.2MHz, 1200Mbps */
					39 00 00 00 00 00 EE A9 02 01 C3 00 00 99 02 01 C3 30 30 00 02 01 C3 0B 0D 3F 20 2F 02 01 C3 11 13 3F 70 2F 02 01 C3 17 17 3F 02 01 C3 18 19 26 2F 02 01 C3 1D 1F 3F 20 2F 02 01 C3 23 25 3F 3A 2F 02 01 C3 0E 0F 3F 62 02 01 C3 10 10 DE 02 01 C3 14 16 3F 62 DE 02 01 C3 1A 1C 3F 62 DE 02 01 C3 20 22 3F 62 DE 02 01 C3 26 27 3F 62 02 01 C3 28 28 DE 02 01 C3 29 2B 11 11 01 02 01 C3 2C 2E 00 00 00 02 01 C3 31 32 AA 02 02 01 C3 33 34 AA 02 02 01 C3 04 04 E3 02 01 C3 09 09 E4 02 01 C3 01 01 29 02 01 C3 06 06 29 02 01 C3 02 03 02 70 02 01 C3 08 08 70 02 01 EA 00 00 11 02 01 EA 07 07 01 02 01 EA 08 08 39 02 01 EA 0B 0B 11 02 01 EA 12 13 01 AC 02 01 EA 1A 1B 01 39 02 01 EA 1C 1D 01 AC 02 01 C3 04 04 EA 02 01 C3 09 09 EA 02 01 C3 2F 2F 77
					/*DDIC Fast Discharge On*/
					39 00 00 40 00 00 06 F0 55 AA 52 08 01
					15 00 00 40 00 00 02 E4 90
					15 00 00 40 00 00 02 6F 0A
					15 00 00 00 00 00 02 E4 90
					/* Fix TE Width */
					39 00 00 00 00 00 03 35 20 2E
					/* Abnormal power failure */
					39 00 00 00 00 00 06 F0 55 AA 52 08 05
					39 00 00 00 00 00 08 CB 13 13 13 13 13 13 13
					/* Sleep Out */
					05 00 00 00 78 00 02 11 00
					/* Demura offset remapping open */
					39 00 00 40 00 00 06 F0 55 AA 52 08 04
					15 00 00 00 00 00 02 EB 00
					/* Display On */
					05 00 00 00 00 00 02 29 00
				];
				qcom,mdss-dsi-on-command-state = "dsi_lp_mode";
				qcom,mdss-dsi-timing-switch-command = [
					/* 90 Hz cmd_1 */
					15 01 00 00 00 00 02 2F 01
				];
				qcom,mdss-dsi-timing-switch-command-state = "dsi_hs_mode";

				qcom,mdss-dsi-nolp-command = [
					39 00 00 00 0A 00 2A A9 02 01 BA 09 0E 55 55 55 55 AA 3F 02 01 BA 1B 1C 92 92 02 01 BA 27 27 55 02 01 BA 28 2C 55 55 55 AA 3F 02 01 BA 39 3A 92 92
					05 00 00 40 00 00 01 38
					39 00 00 40 00 00 03 51 00 23
					15 00 00 00 00 00 02 2F 01
				];
				qcom,mdss-dsi-nolp-command-update = <0x51 2 2>;
				qcom,mdss-dsi-nolp-command-state = "dsi_hs_mode";
			};
		};
	};
};

&dsi_o11u_42_02_0b_dsc_cmd {
	/* IRQF_ONESHOT | IRQF_TRIGGER_HEIGH */
	mi,esd-err-irq-gpio = <&tlmm 87 0x2004>;
	mi,esd-err-irq-gpio-flag = <0x2004>;
	mi,panel-id = <0x4F313155 0x0042020A>;

	mi,panel-ignore-esd-in-aod;
	mi,panel-dbi-3dlut-compensate-enable;

	mi,ddic-round-corner-enabled;

	mi,local-hbm-enabled;
	mi,local-hbm-white-1000nit-update-flag;
	mi,local-hbm-white-110nit-update-flag;
	mi,local-hbm-alpha-ctrl-aa-area;
	mi,local-hbm-ctrl-df-reg;
	mi,local-hbm-ui-ready-delay-num-frame = <4>; /* 4 frame */
	mi,fod-low-brightness-clone-threshold = <200>;
	mi,fod-low-brightness-lux-threshold = <3>;
	mi,need-fod-animal-in-normal-enabled;

	mi,doze-hbm-dbv-level = <412>;
	mi,doze-lbm-dbv-level = <35>;
	mi,mdss-dsi-fac-bl-max-level = <5460>;
	mi,mdss-fac-brightness-max-level = <5460>;
	mi,disable-ic-dimming-flag;
	mi,panel-on-dimming-delay = <120>;
	mi,panel-build-id-read-needed;
	mi,panel-build-id-read-length = <1>;
	mi,mdss-dsi-panel-build-id-read-command = [06 01 00 01 00 00 01 DA];
	mi,mdss-dsi-panel-build-id-read-command-state = "dsi_hs_mode";

	mi,mdss-dsi-panel-cell-id-read-command = [06 01 00 01 00 00 01 B1];
	mi,mdss-dsi-panel-cell-id-read-pre-tx-command = [
		39 00 00 40 00 00 06 F0 55 AA 52 08 00
		15 00 00 40 00 00 02 EA 10
		39 00 00 00 00 00 06 F0 55 AA 52 00 00
	];
	mi,mdss-dsi-panel-cell-id-read-after-tx-command = [
		39 00 00 40 00 00 06 F0 55 AA 52 08 00
		15 00 00 00 00 00 02 EA 00
	];
	mi,mdss-dsi-panel-cell-id-read-pre-tx-command-state = "dsi_hs_mode";
	mi,mdss-dsi-panel-cell-id-read-after-tx-command-state = "dsi_hs_mode";
	mi,mdss-dsi-panel-cell-id-read-command-state = "dsi_hs_mode";
	mi,mdss-dsi-panel-cell-id-read-length = <14>;

	mi,mdss-dsi-panel-osc-status-read-command = [06 01 00 01 00 00 01 C3];
	mi,mdss-dsi-panel-osc-status-read-pre-tx-command = [
		39 00 00 40 00 00 06 F0 55 AA 52 08 01
		15 00 00 00 00 00 02 6F 2F
	];
	mi,mdss-dsi-panel-osc-status-read-pre-tx-command-state = "dsi_hs_mode";
	mi,mdss-dsi-panel-osc-status-read-command-state = "dsi_hs_mode";
	mi,mdss-dsi-panel-osc-status-read-length = <1>;

	mi,mdss-dsi-panel-wp-read-command = [06 01 00 01 00 00 01 A3];
	mi,mdss-dsi-panel-wp-read-command-state = "dsi_hs_mode";
	mi,mdss-dsi-panel-wp-read-pre-tx-command = [39 00 00 40 00 00 02 6F 7A];
	mi,mdss-dsi-panel-wp-read-pre-tx-command-state = "dsi_hs_mode";
	mi,mdss-dsi-panel-wp-read-length = <8>;

	mi,flatmode-status-check-enabled;
	mi,mdss-dsi-panel-flatmode-status-command = [
			06 01 00 01 00 00 01 5F
	];
	mi,mdss-dsi-panel-flatmode-status-command-state = "dsi_hs_mode";
	mi,mdss-dsi-panel-flatmode-status-read-length = <1>;
	mi,mdss-dsi-panel-flatmode-on-status-value = <0x00>;
};
